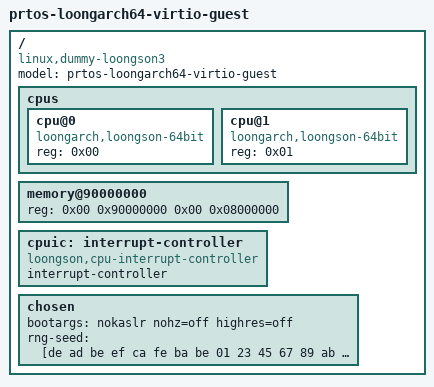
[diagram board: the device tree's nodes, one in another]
/dts-v1/;

/ {
	#address-cells = <0x02>;
	#size-cells = <0x02>;
	compatible = "linux,dummy-loongson3";
	model = "prtos-loongarch64-virtio-guest";

	cpus {
		#address-cells = <0x01>;
		#size-cells = <0x00>;

		cpu@0 {
			device_type = "cpu";
			compatible = "loongarch,loongson-64bit";
			reg = <0x00>;
		};

		cpu@1 {
			device_type = "cpu";
			compatible = "loongarch,loongson-64bit";
			reg = <0x01>;
		};
	};

	memory@90000000 {
		device_type = "memory";
		reg = <0x00 0x90000000 0x00 0x08000000>;
	};

	cpuic: interrupt-controller {
		compatible = "loongson,cpu-interrupt-controller";
		#interrupt-cells = <0x01>;
		interrupt-controller;
	};

	chosen {
		bootargs = "nokaslr nohz=off highres=off";
		rng-seed = [de ad be ef ca fe ba be 01 23 45 67 89 ab cd ef
		            fe dc ba 98 76 54 32 10 a0 b1 c2 d3 e4 f5 06 17
		            28 39 4a 5b 6c 7d 8e 9f 10 21 32 43 54 65 76 87
		            98 a9 ba cb dc ed fe 0f 11 22 33 44 55 66 77 88];
	};
};
